# DSS_HW_ACC register map
Vendor: Texas Instruments
Peripheral module from a debugger description file (folder radar).
Registers are 32-bit, read-only, no defined reset value unless marked. A register's access mark holds for its fields unless they carry their own. Offsets are as the file gives them; lines under a group give offsets from that group; [hi:lo] are bit positions; {n}, {i} and the like mark numbered series; 'fields as' and 'values as' point back to an identical list; <NAME> marks a mode.

## DSS_HW_ACC
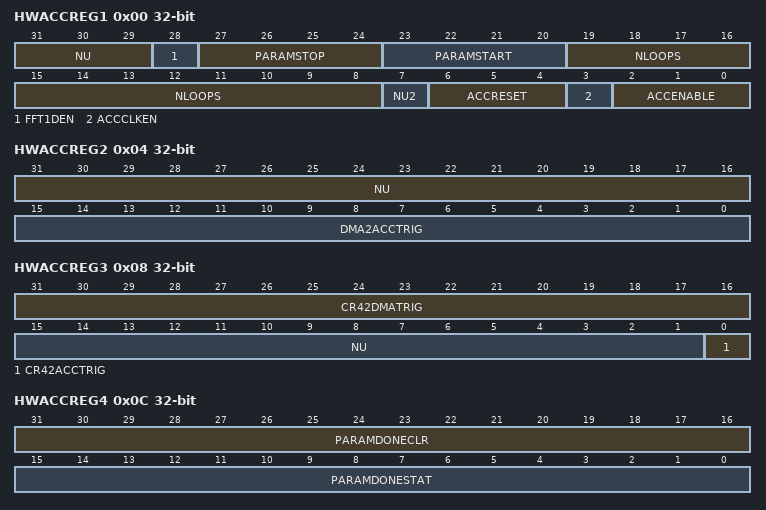
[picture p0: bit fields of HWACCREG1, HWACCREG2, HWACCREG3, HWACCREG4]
0x00 HWACCREG1 access per field
  [31:29] NU ro
  [28] FFT1DEN rw — ADC buffer sharing mode (AR14xx): This register is relevant in AR14xx, where the Radar Hardware Accelerator is included in a single device along with the mmWave RF front-end. In such a case, during active chirp transmission and inline 1st dimension FFT processing, the ACCEL_MEM0 and ACCEL_MEM1 memories of the accelerator are shared as ping-pong ADC buffers. This register bit needs to be set during this time, so that while the Digital Front End writes ADC samples to the ping buffer, the accelerator automatically accesses (only) the pong buffer, and vice versa. At the end of the active transmission portion of a frame, this bit can be cleared, so that the accelerator has access to all the four local memories independently.
  [27:24] PARAMSTOP rw — These registers are used to control the start and stop index of the parameter-set through which the state machine loops through. The state machine starts at the parameter-set specified by PARAM_START and loads each parameter-set one after another and runs the accelerator as per that configuration. When the state machine reaches the parameter-set specified by PARAM_STOP, it loops back to the start index as specified by PARAM_START.
  [23:20] PARAMSTART rw — These registers are used to control the start and stop index of the parameter-set through which the state machine loops through. The state machine starts at the parameter-set specified by PARAM_START and loads each parameter-set one after another and runs the accelerator as per that configuration. When the state machine reaches the parameter-set specified by PARAM_STOP, it loops back to the start index as specified by PARAM_START.
  [19:8] NLOOPS rw — Number of loops: This register controls the number of times the State Machine will loop through the parameter-sets (from a programmed start index till a programmed end index) and run them. The maximum number of times the loop can be made is run is 4094. A value of zero programmed in this register means that the looping mechanism is disabled.
  [7] NU2 ro
  [6:4] ACCRESET rw — Software Reset Control: This register provides software reset control for the Radar Hardware Accelerator. The assertion of these register bits by the main processor will bring the Accelerator Engine to a known reset state. This is mostly applicable for resetting the accelerator in case of unexpected behavior. The sequence to be followed in case software reset is to write 111b to this register and then a 000b
  [3] ACCCLKEN rw — Clock-gating Control: This register bit controls the enable/disable for the clock of the Radar Accelerator. This register bit can be set to 0 to clock-gate the accelerator when not using the accelerator. Before enabling the accelerator or before configuring the accelerator’s registers, this register bit should be set first, so that the clock is available
  [2:0] ACCENABLE rw — Enable/Disable Control: A value of ACC_ENABLE = 111b enables the Radar Hardware Accelerator and any other value of the register keeps the Accelerator Engine in disabled state.
0x04 HWACCREG2 access not given
  [31:16] NU ro
  [15:0] DMA2ACCTRIG — DMA trigger register: This register is relevant whenever DMA triggered mode is used (i.e., TRIGMODE = 011b). Whenever a DMA channel has finished copying input samples into the local memory of the accelerator and wants to trigger the accelerator, the procedure to follow is to use a second linked DMA channel to write a 16-bit one-hot signature into this register to trigger the accelerator. In DMA triggered mode, the State Machine keeps monitoring this 16-bit register and waits as long as a specific bit (see DMA2ACC_CHANNEL_TRIGSRC) in this register is zero. The second linked DMA channel writes a one-hot signature that sets the specific bit, so that the State Machine gets triggered and starts the accelerator operations for that parameter-set.
0x08 HWACCREG3 access not given
  [31:16] CR42DMATRIG — Override accelerator Trigger to DMA.Can be used for triggering the first and second DMA transfer thorugh processor
  [15:1] NU ro
  [0] CR42ACCTRIG — Software trigger bit: This register bit is relevant whenever software triggered mode is used (i.e., TRIGMODE = 001b). The main processor software can set this register bit, so that the State Machine gets triggered and starts the accelerator operations for that parameter-set.
0x0C HWACCREG4 access not given
  [31:16] PARAMDONECLR — Status bits in PARAMDONESTAT are not automatically cleared, but they can be individually cleared by writing to 16-bit register PARAM_DONE_CLR.
  [15:0] PARAMDONESTAT ro — Parameter-set done status: This read-only status register can be used by the main processor to see which parameter-sets are complete that led to the interrupt to the main processor. The individual bits in this 16-bit status register indicate which of the 16 parameter-sets have completed.
0x10 HWACCREG5 rw
  [31:0] BPMPATTERNMSB — BPM pattern MSB: Specifies the BPM pattern to be used to multiply the input samples if BPM removal is enabled
0x14 HWACCREG6 rw
  [31:0] BPMPATTERNLSB — BPM pattern LSB: Specifies the BPM pattern to be used to multiply the input samples if BPM removal is enabled
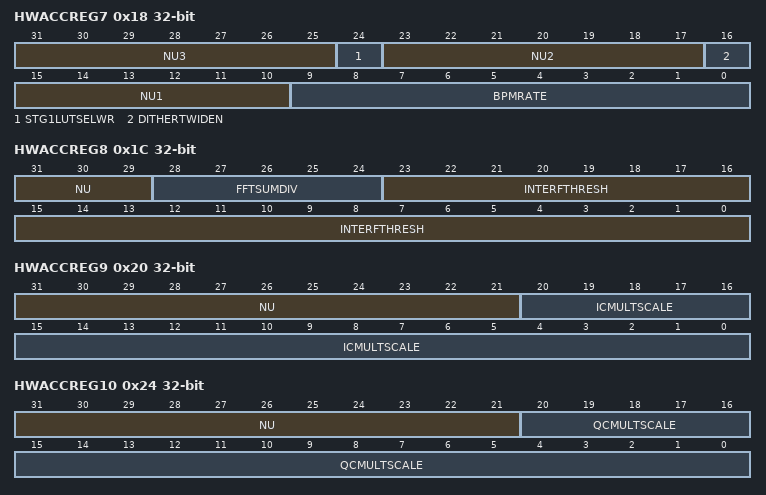
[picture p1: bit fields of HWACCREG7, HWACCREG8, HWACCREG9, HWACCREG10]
0x18 HWACCREG7 access per field
  [31:25] NU3 ro
  [24] STG1LUTSELWR rw — Select Window RAM or Internal RAM: The Internal RAM for Vector Multiplication mode is mapped to the same address space as the Window RAM – Hence, this register bit is required to specify which of these two needs to be selected, when loading the co-efficients via DMA or R4F. ‘0’-> Window RAM is selected ‘1’-> Internal RAM for Vector Multiplication mode is selected. Keep this register bit as 0 always, except during the period when Internal RAM needs to be loaded.
  [23:17] NU2 ro
  [16] DITHERTWIDEN rw — Twiddle factor dithering enable: This register-bit is used to enable/disable dithering of twiddle factors in the FFT.
  [15:10] NU1 ro
  [9:0] BPMRATE rw — BPM rate: Specifies the number of input samples corresponding to each BPM bit. Minimum valid value for this register is 1.
0x1C HWACCREG8 access per field
  [31:29] NU ro
  [28:24] FFTSUMDIV rw — Right-shifting for Sum Statistic: This register specifies how many LSBs to drop to convert the sum statistics to 24-bit value going to the Output Formatter
  [23:0] INTERFTHRESH rw — Interference threshold: This register is used to specify the threshold for zero-ing out samples affected by interference. Any sample whose magnitude exceeds this threshold is zero-ed out, if the feature is enabled using INTERF_THRESH_EN register bit in HW_ACC_PARAM register set
0x20 HWACCREG9 access per field
  [31:21] NU ro
  [20:0] ICMULTSCALE rw — In Scalar Multiplication mode(CMULT_MODE in HW_ACC_PARAM register set = 101b) , the complex multiplier will multiply each input sample with a 21-bit scalar complex number that is programmed in I_CMULT_SCALE and Q_CMULT_SCALE registers
0x24 HWACCREG10 access per field
  [31:21] NU ro
  [20:0] QCMULTSCALE rw — In Scalar Multiplication mode(CMULT_MODE in HW_ACC_PARAM register set = 101b) , the complex multiplier will multiply each input sample with a 21-bit scalar complex number that is programmed in I_CMULT_SCALE and Q_CMULT_SCALE registers
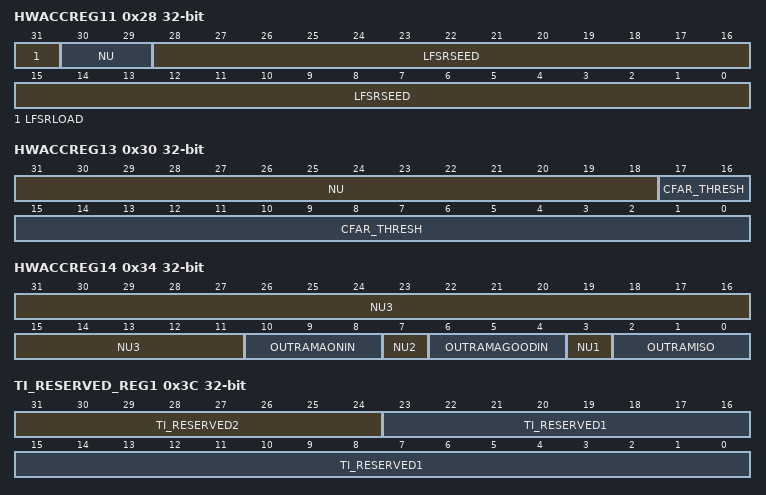
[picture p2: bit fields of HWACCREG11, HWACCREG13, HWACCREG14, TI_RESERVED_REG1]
0x28 HWACCREG11 access not given
  [31] LFSRLOAD — To load the LFSR seed, a pulse signal needs to be provided, by writing a 1 to the LFSR_LOAD register-bit. Self clearing
  [30:29] NU ro
  [28:0] LFSRSEED rw — LFSR seed value (random pattern) for twiddle factor dithering,
0x2C HWACCREG12 access not given
  [31:25] NU2 rw
  [23:19] NU1 ro
  [19] ACC_TRIGGER_IN_CLR — Clear trigger status read-only register: This register-bit when set clears the trigger status register ACC_TRIG_IN_STAT described above
  [18:0] ACC_TRIGGER_IN_STAT ro — Debug register for trigger status: This is a read-only status register, which indicates the trigger status of the accelerator, i.e., whether a specific DMA trigger or a Ping-pong trigger or a SW trigger was ever received (refer TRIGMODE in HW_ACC_PARAM register set). The MSB 16 bits of this register indicate whether a trigger was received via DMA trigger method. The next two bits (i.e., bit indices 2 and 1) indicate the status of DFE ping-pong switch-based trigger and SW trigger respectively. The LSB bit is always 1 and can be ignored {DMA2ACCTRIG[15:0],adc_buffer_done,CR42ACCTRIG,1}
0x30 HWACCREG13 access per field
  [31:18] NU ro
  [17:0] CFAR_THRESH rw — CFAR Threshold scale factor: This value is used to either multiply or add to the ‘surrounding noise average’ to determine the threshold used for detection of the present cell under test. If logarithmic CFAR mode is disabled (i.e., in magnitude or magnitude-squared mode), then the register value is multiplied with the surrounding noise average to determine the threshold, else it is added to the surrounding noise average. In the former case, this 18-bit register is interpreted as a 14.4 value. In the latter case (i.e., logarithmic mode), the 18-bit register is interpreted as a 7.11 value.
0x34 HWACCREG14 access per field
  [31:11] NU3 rw
  [10:8] OUTRAMAONIN rw — Control for powering down ACCEL_MEM*. Reserved. Do not change Default value
  [7] NU2 ro
  [6:4] OUTRAMAGOODIN rw — Control for powering down ACCEL_MEM*. Reserved. Do not change Default value
  [3] NU1 ro
  [2:0] OUTRAMISO rw — Control for powering down ACCEL_MEM*. Reserved. Do not change Default value
0x38 HWACCREG15 rw
  [31:0] SPARE2
0x3C TI_RESERVED_REG1 access per field
  [31:24] TI_RESERVED2 ro — TI Reserved register
  [23:0] TI_RESERVED1 rw — TI Reserved register
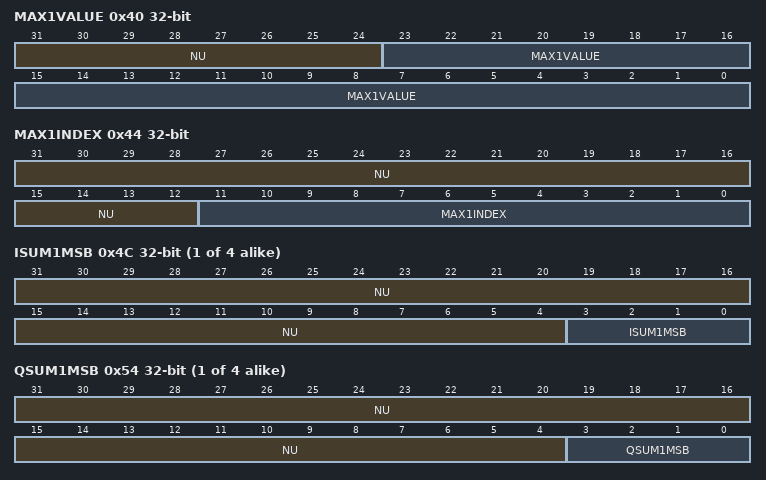
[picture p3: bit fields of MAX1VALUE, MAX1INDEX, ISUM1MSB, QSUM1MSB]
0x40 MAX1VALUE
  [31:24] NU
  [23:0] MAX1VALUE — Max value: These registers contain the max value on a per-iteration basis. These registers are meaningful only when Magnitude or Log-Magnitude is enabled. Only the max values for up to four iterations are recorded in these registers. For larger number of iterations, use Statistics output mode (FFT_OUT_MODE in HW_ACC_PARAM register set).
0x44 MAX1INDEX
  [31:12] NU
  [11:0] MAX1INDEX — Max index: These registers contain the max index on a per-iteration basis, corresponding to each max value in the MAXn_VALUE registers.
0x48 ISUM1LSB
  [31:0] ISUM1LSB — Sum statistics: These registers contain the sum of the I outputs and Q outputs on a per-iteration basis. Only the statistics for up to four iterations are recorded in these registers. For larger number of iterations, use Statistics output mode (FFT_OUT_MODE in HW_ACC_PARAM register set).
{0x34+0x18*i} ISUM{i}MSB (i=1..4)
  [31:4] NU
  [3:0] ISUM{i}MSB — Refer ISUM1LSB
{0x38+0x18*i} QSUM{i}LSB (i=1..4)
  [31:0] QSUM{i}LSB — Refer ISUM1LSB
{0x3C+0x18*i} QSUM{i}MSB (i=1..4)
  [31:4] NU
  [3:0] QSUM{i}MSB — Refer ISUM1LSB
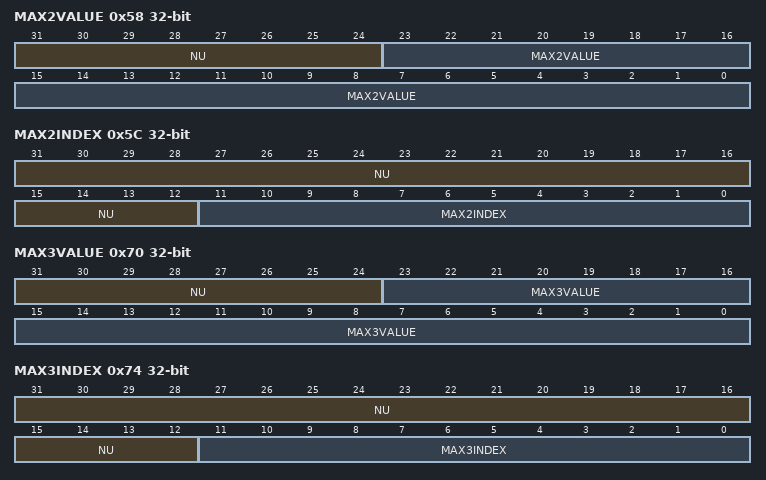
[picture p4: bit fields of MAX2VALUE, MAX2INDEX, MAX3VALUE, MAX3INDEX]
0x58 MAX2VALUE
  [31:24] NU
  [23:0] MAX2VALUE — Refer MAX1VALUE
0x5C MAX2INDEX
  [31:12] NU
  [11:0] MAX2INDEX — Refer MAX1INDEX
{0x30+0x18*i} ISUM{i}LSB (i=2..4)
  [31:0] ISUM{i}LSB — Refer ISUM1LSB
0x70 MAX3VALUE
  [31:24] NU
  [23:0] MAX3VALUE — Refer MAX1VALUE
0x74 MAX3INDEX
  [31:12] NU
  [11:0] MAX3INDEX — Refer MAX1INDEX
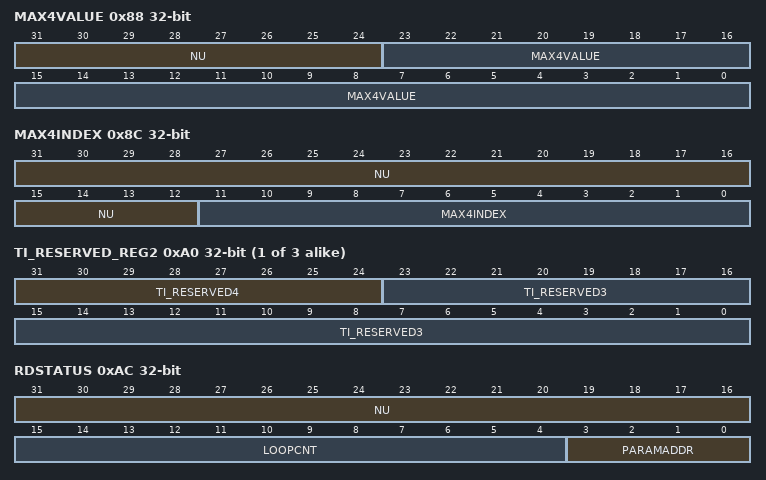
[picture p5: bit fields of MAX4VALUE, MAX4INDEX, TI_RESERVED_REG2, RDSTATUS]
0x88 MAX4VALUE
  [31:24] NU
  [23:0] MAX4VALUE — Refer MAX1INDEX
0x8C MAX4INDEX
  [31:12] NU
  [11:0] MAX4INDEX — Refer MAX1VALUE
{0x98+4i} TI_RESERVED_REG{i} access per field (i=2..4)
  [31:24] TI_RESERVED{2i} ro — TI Reserved register
  [23:0] TI_RESERVED{2i-1} rw — TI Reserved register
0xAC RDSTATUS
  [31:16] NU
  [15:4] LOOPCNT — Running value of the loop count when the HWA is executing from PARAM RAM . For Debug only
  [3:0] PARAMADDR — Index of the current parameter set being executed from PARAM RAM . For Debug only
0xB0 SIGDMACH1DONE
  [31:0] SIGDMACH1DONE — Signature for DMA channel 1 completion (tied to “0x0001”in HW). Linked DMA can copy from one of these ‘SIG_DMACHx_DONE’ registers into DMA2ACC_TRIG register to set the appropriate register bit to signal the completion of DMA and trigger the accelerator
0xB4 SIGDMACH2DONE
  [31:0] SIGDMACH2DONE — Signature for DMA channel 2 completion (tied to “0x0002” in HW)
0xB8 SIGDMACH3DONE
  [31:0] SIGDMACH3DONE — Signature for DMA channel 3 completion (tied to “0x0004”in HW)
0xBC SIGDMACH4DONE
  [31:0] SIGDMACH4DONE — Signature for DMA channel 4 completion (tied to “0x0008” in HW)
0xC0 SIGDMACH5DONE
  [31:0] SIGDMACH5DONE — Signature for DMA channel 5 completion (tied to “0x0010” in HW)
0xC4 SIGDMACH6DONE
  [31:0] SIGDMACH6DONE — Signature for DMA channel 6 completion (tied to “0x0020” in HW)
0xC8 SIGDMACH7DONE
  [31:0] SIGDMACH7DONE — Signature for DMA channel 7 completion (tied to “0x0040” in HW)
0xCC SIGDMACH8DONE
  [31:0] SIGDMACH8DONE — Signature for DMA channel 8 completion (tied to “0x0080” in HW)
0xD0 SIGDMACH9DONE
  [31:0] SIGDMACH9DONE — Signature for DMA channel 9 completion (tied to “0x0100” in HW)
0xD4 SIGDMACH10DONE
  [31:0] SIGDMACH10DONE — Signature for DMA channel 10 completion (tied to “0x0200” in HW)
0xD8 SIGDMACH11DONE
  [31:0] SIGDMACH11DONE — Signature for DMA channel 11 completion (tied to “0x0040” in HW)
0xDC SIGDMACH12DONE
  [31:0] SIGDMACH12DONE — Signature for DMA channel 12 completion (tied to “0x0080” in HW)
0xE0 SIGDMACH13DONE
  [31:0] SIGDMACH13DONE — Signature for DMA channel 13 completion (tied to “0x1000” in HW)
0xE4 SIGDMACH14DONE
  [31:0] SIGDMACH14DONE — Signature for DMA channel 14 completion (tied to “0x2000” in HW)
0xE8 SIGDMACH15DONE
  [31:0] SIGDMACH15DONE — Signature for DMA channel 15 completion (tied to “0x4000” in HW)
0xEC SIGDMACH16DONE
  [31:0] SIGDMACH16DONE — Signature for DMA channel 16 completion (tied to “0x8000” in HW)
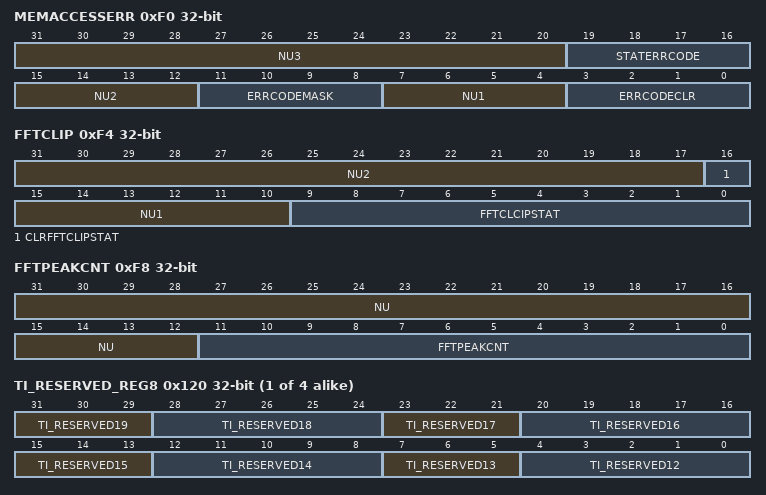
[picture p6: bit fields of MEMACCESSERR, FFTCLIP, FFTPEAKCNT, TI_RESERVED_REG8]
0xF0 MEMACCESSERR access not given
  [31:20] NU3 ro
  [19:16] STATERRCODE ro — Error status : Memory access error: This 4-bit read-only register indicates if there is a memory access error caused by incorrect configuration or usage of the accelerator, where both the DMA and the accelerator are attempting to access the same 16KB memory at the same time. The 4-bit register indicates the error status for the 4 16KB memories (MSB bit corresponds to ACCEL_MEM0).
  [15:12] NU2 ro
  [11:8] ERRCODEMASK rw — Mask for STATERRCODE This register can be used to mask the memory access error. If set, the memory access error indication is disabled.
  [7:4] NU1 ro
  [3:0] ERRCODECLR — Clear memory access error: This register can be used to clear the memory access error indication. Setting this register clears the error indication.
0xF4 FFTCLIP access not given
  [31:17] NU2 ro
  [16] CLRFFTCLIPSTAT — FFTCLCIPSTAT can be cleared by setting single-bit register CLRFFTCLIPSTAT, so that the saturation status indication gets cleared back to 0 and any subsequent saturation events can be freshly monitored.
  [15:10] NU1 ro
  [9:0] FFTCLCIPSTAT ro — FFT Clip Status (read-only): This is a read-only status register, which indicates any saturation/clipping events that have happened in the FFT butterfly stages. Note that each of the 10 butterfly stages in the FFT can be programmed to either saturate the MSB or round the LSB. Whenever saturation of MSB is used in any stage, there is a possibility that that stage can saturate/clip samples. In that case, this saturation event is indicated in the corresponding bit in this status registert. If multiple FFTs are performed, this status register includes any saturation events happening in any of them.
0xF8 FFTPEAKCNT
  [31:12] NU
  [11:0] FFTPEAKCNT — CFAR Detected Peak Count: This is a read-only register that contains the number of detected peaks that are logged in the destination memory, when CFAR Engine is configured in ‘Detected Peaks List’ mode.
{0xE8+4i} TI_RESERVED_REG{i} (i=5..7)
  [31:0] TI_RESERVED{i+4} — TI Reserved register
{0x100+4i} TI_RESERVED_REG{i} access per field (i=8..11)
  [31:29] TI_RESERVED{8i-45} ro — TI Reserved register
  [28:24] TI_RESERVED{8i-46} rw — TI Reserved register
  [23:21] TI_RESERVED{8i-47} ro — TI Reserved register
  [20:16] TI_RESERVED{8i-48} rw — TI Reserved register
  [15:13] TI_RESERVED{8i-49} ro — TI Reserved register
  [12:8] TI_RESERVED{8i-50} rw — TI Reserved register
  [7:5] TI_RESERVED{8i-51} ro — TI Reserved register
  [4:0] TI_RESERVED{8i-52} rw — TI Reserved register
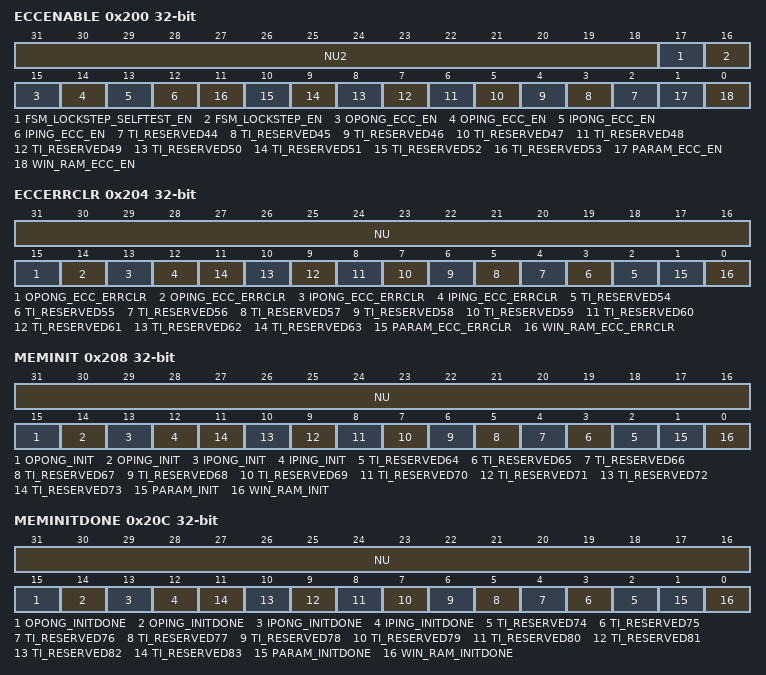
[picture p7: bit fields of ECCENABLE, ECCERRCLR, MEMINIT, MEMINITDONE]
0x200 ECCENABLE access per field
  [31:18] NU2 ro
  [17] FSM_LOCKSTEP_SELFTEST_EN rw — ‘1’: Enable Selftest for Accelerator FSM
  [16] FSM_LOCKSTEP_EN rw — ‘1’: Enable Lockstep for Accelerator FSM
  [15] OPONG_ECC_EN rw — ‘1’: Enable ECC for ACCEL_MEM3
  [14] OPING_ECC_EN rw — ‘1’: Enable ECC for ACCEL_MEM2
  [13] IPONG_ECC_EN rw — ‘1’: Enable ECC for ACCEL_MEM1
  [12] IPING_ECC_EN rw — ‘1’: Enable ECC for ACCEL_MEM0
  [n-42] TI_RESERVED{n} rw (n=44..53) — TI Reserved register
  [1] PARAM_ECC_EN rw — ‘1’: Enable ECC for Parameter set RAM
  [0] WIN_RAM_ECC_EN rw — ‘1’: Enable ECC for Window RAM
0x204 ECCERRCLR access not given
  [31:16] NU ro
  [15] OPONG_ECC_ERRCLR — '1': Clear Error registers(status,address and bit location) for ACCEL_MEM3
  [14] OPING_ECC_ERRCLR — '1': Clear Error registers(status,address and bit location) for ACCEL_MEM2
  [13] IPONG_ECC_ERRCLR — '1': Clear Error registers(status,address and bit location) for ACCEL_MEM1
  [12] IPING_ECC_ERRCLR — '1': Clear Error registers(status,address and bit location) for ACCEL_MEM0
  [n-52] TI_RESERVED{n} (n=54..63) — TI Reserved register
  [1] PARAM_ECC_ERRCLR — '1': Clear Error registers(address and bit location) for Parameter set RAM
  [0] WIN_RAM_ECC_ERRCLR — '1': Clear Error registers(address and bit location) for Window RAM
0x208 MEMINIT access not given
  [31:16] NU ro
  [15] OPONG_INIT — '1': Start initialing ACCEL_MEM3 with all '0's
  [14] OPING_INIT — '1': Start initialing ACCEL_MEM2 with all '0's
  [13] IPONG_INIT — '1': Start initialing ACCEL_MEM1 with all '0's
  [12] IPING_INIT — '1': Start initialing ACCEL_MEM0 with all '0's
  [n-62] TI_RESERVED{n} (n=64..73) — TI Reserved register
  [1] PARAM_INIT — '1': Start initialing Parameter set RAM with all '0's
  [0] WIN_RAM_INIT — '1': Start initialing Window RAM with all '0's
0x20C MEMINITDONE
  [31:16] NU
  [15] OPONG_INITDONE — '1': Init done status for ACCEL_MEM3
  [14] OPING_INITDONE — '1': Init done status for ACCEL_MEM2
  [13] IPONG_INITDONE — '1': Init done status for ACCEL_MEM1
  [12] IPING_INITDONE — '1': Init done status for ACCEL_MEM0
  [n-72] TI_RESERVED{n} (n=74..83) — TI Reserved register
  [1] PARAM_INITDONE — '1': Init done status for Parameter set RAM
  [0] WIN_RAM_INITDONE — '1': Init done status for Window RAM
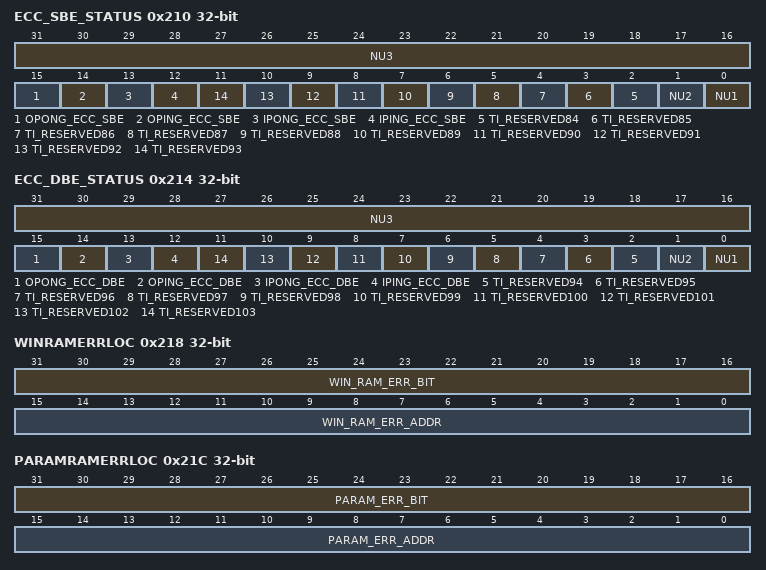
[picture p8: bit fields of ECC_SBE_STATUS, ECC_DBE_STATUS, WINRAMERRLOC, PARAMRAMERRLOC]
0x210 ECC_SBE_STATUS
  [31:16] NU3
  [15] OPONG_ECC_SBE — '1': Single bit error status for ACCEL_MEM3
  [14] OPING_ECC_SBE — '1': Single bit error status for ACCEL_MEM2
  [13] IPONG_ECC_SBE — '1': Single bit error status for ACCEL_MEM1
  [12] IPING_ECC_SBE — '1': Single bit error status for ACCEL_MEM0
  [n-82] TI_RESERVED{n} (n=84..93) — TI Reserved register
  [1] NU2
  [0] NU1
0x214 ECC_DBE_STATUS
  [31:16] NU3
  [15] OPONG_ECC_DBE — '1': Double bit error status for ACCEL_MEM3
  [14] OPING_ECC_DBE — '1': Double bit error status for ACCEL_MEM2
  [13] IPONG_ECC_DBE — '1': Double bit error status for ACCEL_MEM1
  [12] IPING_ECC_DBE — '1': Double bit error status for ACCEL_MEM0
  [n-92] TI_RESERVED{n} (n=94..103) — TI Reserved register
  [1] NU2
  [0] NU1
0x218 WINRAMERRLOC
  [31:16] WIN_RAM_ERR_BIT — [Debug] Single bit error location within error address of Window RAM
  [15:0] WIN_RAM_ERR_ADDR — [Debug] Address of SBE/DBE location within Window RAM
0x21C PARAMRAMERRLOC
  [31:16] PARAM_ERR_BIT — [Debug]Single bit error location within error address of Parameter set RAM
  [15:0] PARAM_ERR_ADDR — [Debug] Address of SBE/DBE location within Parameter set RAM
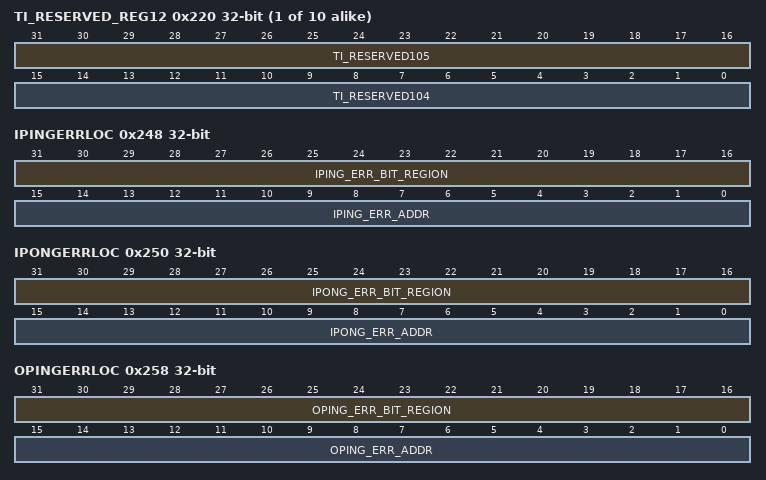
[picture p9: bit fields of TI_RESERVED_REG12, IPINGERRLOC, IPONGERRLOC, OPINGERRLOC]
{0x1F0+4i} TI_RESERVED_REG{i} (i=12..21)
  [31:16] TI_RESERVED{2i+81} — TI Reserved register
  [15:0] TI_RESERVED{2i+80} — TI Reserved register
0x248 IPINGERRLOC
  [31:16] IPING_ERR_BIT_REGION — [Debug] [16]->1 , SBE is located in Region0 (column [15: 0] ) [17]->1 , SBE is located in Region1 (column [31:16] ) [18]->1 , SBE is located in Region2 (column [47:32] ) [19]->1 , SBE is located in Region3 (column [63:48] ) [20]->1 , SBE is located in Region4 (column [79:63] ) [21]->1 , SBE is located in Region5 (column [95:80] ) [23]->1 , SBE is located in Region6 (column [127:96] )
  [15:0] IPING_ERR_ADDR — [Debug ]Address of error location – rows 0-1023
0x24C IPINGSBELOC
  [31:0] IPING_ERR_BIT_LOC — [Debug] [3:0]->SBE bit location in region0 [7:4]->SBE bit location in region1 [11:8]->SBE bit location in region2 [15:12]->SBE bit location in region3 [19:16]->SBE bit location in region4 [23:20]->SBE bit location in region5 [27:24]->SBE bit location in region6 [31:28]->SBE bit location in region7
0x250 IPONGERRLOC
  [31:16] IPONG_ERR_BIT_REGION — [Debug] Refer IPING_ERR_BIT_LOC
  [15:0] IPONG_ERR_ADDR — [Debug] Refer IPING_ERR_BIT_REGION
0x254 IPONGSBELOC
  [31:0] IPONG_ERR_BIT_LOC — [Debug] Refer IPING_ERR_BIT_REGION
0x258 OPINGERRLOC
  [31:16] OPING_ERR_BIT_REGION — [Debug] Refer IPING_ERR_BIT_REGION
  [15:0] OPING_ERR_ADDR — [Debug] Refer IPING_ERR_BIT_LOC
0x25C OPINGSBELOC
  [31:0] OPING_ERR_BIT_LOC — [Debug] Refer IPING_ERR_BIT_LOC
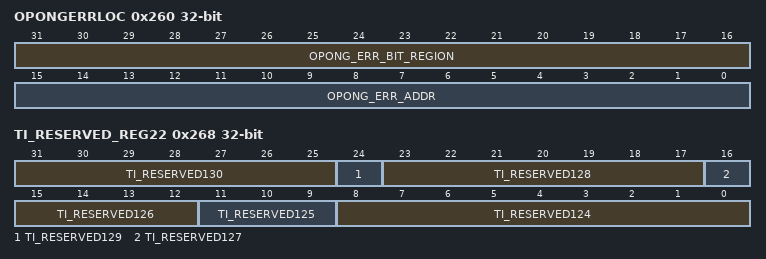
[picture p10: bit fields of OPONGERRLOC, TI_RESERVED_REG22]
0x260 OPONGERRLOC
  [31:16] OPONG_ERR_BIT_REGION — [Debug] Refer IPING_ERR_BIT_LOC
  [15:0] OPONG_ERR_ADDR — [Debug] Refer IPING_ERR_BIT_REGION
0x264 OPONGSBELOC
  [31:0] OPONG_ERR_BIT_LOC — [Debug] Refer IPING_ERR_BIT_REGION
0x268 TI_RESERVED_REG22 access not given
  [31:25] TI_RESERVED130 ro — TI Reserved register
  [24] TI_RESERVED129 rw — TI Reserved register
  [23:17] TI_RESERVED128 ro — TI Reserved register
  [16] TI_RESERVED127 — TI Reserved register
  [15:12] TI_RESERVED126 ro — TI Reserved register
  [11:9] TI_RESERVED125 rw — TI Reserved register
  [8:0] TI_RESERVED124 rw — TI Reserved register
0x26C TI_RESERVED_REG23 rw
  [31:0] TI_RESERVED131 — TI Reserved register
0x270 TI_RESERVED_REG24
  [31:0] TI_RESERVED132 — TI Reserved register
